# G32R430xx register map
Vendor: Geehy Semiconductor Co., Ltd.; Series: G32R4; File version: 1.0
CPU: CM52 r0p1, little endian, MPU, no FPU, DSP, VTOR, 4 interrupt priority bits
Registers are 32-bit, read-write, reset 0x0 unless marked. A register's access mark holds for its fields unless they carry their own. Offsets are from the block's base; [hi:lo] are bit positions; {n}, {i} and the like mark numbered series.

## COMP — Comparator
Base 0x40003400
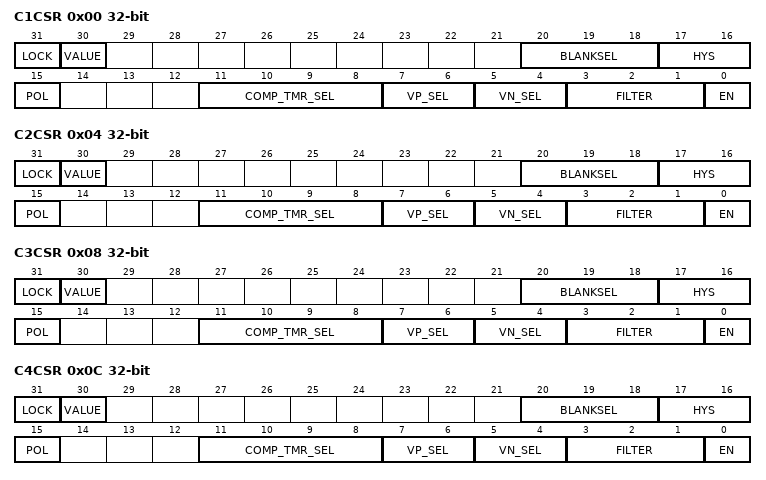
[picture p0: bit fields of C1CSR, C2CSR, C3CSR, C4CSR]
0x00 C1CSR access per field — Comparator 1 control register.
  [31] LOCK rw
  [30] VALUE ro — Comparator outputs the level value before polarity selector and shielding.
  [20:18] BLANKSEL rw — Shielded signal for comparator channel selection.
  [17:16] HYS rw — Delay function enabled
  [15] POL rw — The output polarity of comparator .
  [11:8] COMP_TMR_SEL rw
  [7:6] VP_SEL rw — Comparator 1 positive input voltage select
  [5:4] VN_SEL rw — Comparator 1 negative terminal input voltage select
  [3:1] FILTER rw — Comparator Digital Filter Timing Selection
  [0] EN rw — Module enablement
0x04 C2CSR access per field — Comparator 2 control register.
  [31] LOCK rw
  [30] VALUE ro — Comparator outputs the level value before polarity selector and shielding.
  [20:18] BLANKSEL rw — Shielded signal for comparator channel selection.
  [17:16] HYS rw — Delay function enabled
  [15] POL rw — The output polarity of comparator .
  [11:8] COMP_TMR_SEL rw
  [7:6] VP_SEL rw — Comparator 2 positive input voltage select
  [5:4] VN_SEL rw — Comparator 2 negative terminal input voltage select
  [3:1] FILTER rw — Comparator Digital Filter Timing Selection
  [0] EN rw — Module enablement
0x08 C3CSR access per field — Comparator 3 control register.
  [31] LOCK rw
  [30] VALUE ro — Comparator outputs the level value before polarity selector and shielding.
  [20:18] BLANKSEL rw — Shielded signal for comparator channel selection.
  [17:16] HYS rw — Delay function enabled
  [15] POL rw — The output polarity of comparator .
  [11:8] COMP_TMR_SEL rw
  [7:6] VP_SEL rw — Comparator 3 positive input voltage select
  [5:4] VN_SEL rw — Comparator 3 negative terminal input voltage select
  [3:1] FILTER rw — Comparator Digital Filter Timing Selection
  [0] EN rw — Module enablement
0x0C C4CSR access per field — Comparator 4 control register.
  [31] LOCK rw
  [30] VALUE ro — Comparator outputs the level value before polarity selector and shielding.
  [20:18] BLANKSEL rw — Shielded signal for comparator channel selection.
  [17:16] HYS rw — Delay function enabled
  [15] POL rw — The output polarity of comparator .
  [11:8] COMP_TMR_SEL rw
  [7:6] VP_SEL rw — Comparator 4 positive input voltage select
  [5:4] VN_SEL rw — Comparator 4 negative terminal input voltage select
  [3:1] FILTER rw — Comparator Digital Filter Timing Selection
  [0] EN rw — Module enablement

## PMU — Power manage unit
Base 0x40003800
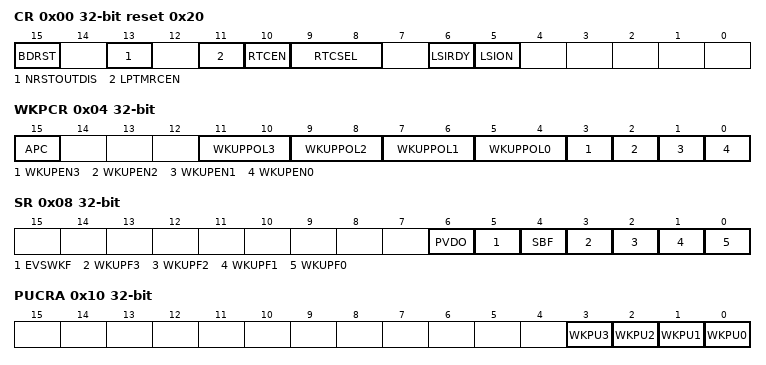
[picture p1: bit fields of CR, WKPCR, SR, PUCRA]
0x00 CR reset 0x20 — Control Register
  [15] BDRST — Reset the bkup area
  [13] NRSTOUTDIS — NRST output pulse to NRST pin enable
  [11] LPTMRCEN — LPTMR clock enable
  [10] RTCEN — RTC clock enable
  [9:8] RTCSEL — RTC Clock Selection
  [6] LSIRDY — LSI Ready Flag Bit
  [5] LSION — LSI Enable
0x04 WKPCR access per field — Low Power Consumption Wake-Up Control Register
  [15] APC rw — Select the status of GPIO when entering standby mode.
  [11:10] WKUPPOL3 rw — The Wake-up Polarity of PD9-WUIO
  [9:8] WKUPPOL2 ro — The Wake-up Polarity of PD0-WUIO
  [7:6] WKUPPOL1 rw — The Wake-up Polarity of PC2-WUIO
  [5:4] WKUPPOL0 rw — The Wake-up Polarity of PC1-WUIO
  [3] WKUPEN3 rw — Activate PD9-WUIO Enable
  [2] WKUPEN2 rw — Activate PD0-WUIO Enable
  [1] WKUPEN1 rw — Activate PC2-WUIO Enable
  [0] WKUPEN0 rw — Activate PC1-WUIO Enable
0x08 SR access per field — Status Register
  [6] PVDO ro — PVD Output 1: VDD voltage is higher than the set value of pvdthsel 0: VDD voltage is lower than the set value of pvdthsel
  [5] EVSWKF rw — EVS wake-up flag, the EVS function can only be used in standby mode.
  [4] SBF rw — 1: The device has entered standby mode. 0: The device has not entered standby mode.
  [3] WKUPF3 rw — The Wake-Up Flag of PD9-WUIO
  [2] WKUPF2 rw — The Wake-Up Flag of PD0-WUIO
  [1] WKUPF1 rw — The Wake-Up Flag of PC2-WUIO
  [0] WKUPF0 rw — The Wake-Up Flag of PC1-WUIO
0x10 PUCRA — Wake up IO pull-up control register
  [n] WKPU{n} (n=0..3) — In standby mode, when APC is enabled, this position is 1, corresponding to the IO being in a pull-up state.
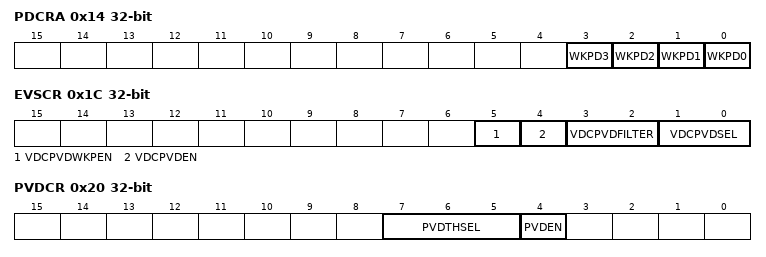
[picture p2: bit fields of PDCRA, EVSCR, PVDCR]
0x14 PDCRA — Wake-up IO Pull-down Control Register
  [n] WKPD{n} (n=0..3) — In standby mode, when APC is enabled, this position is 1, corresponding to the IO being in a pull-down state.
0x1C EVSCR — Power-off Wake-up Control Register
  [5] VDCPVDWKPEN — EVS Pin STANDBY Mode Wake-Up Enable
  [4] VDCPVDEN — EVS Pin Wake-up Enable
  [3:2] VDCPVDFILTER — EVS Pin Filter Configuration
  [1:0] VDCPVDSEL — VDC-VPD Threshold Selection
0x20 PVDCR — PVD Control Register
  [7:5] PVDTHSEL — The detection threshold switch of the programmable voltage detector ranges from a minimum of 2.15V to a maximum of 2.98V, with a default of 000.
  [4] PVDEN — PVD Enable Control Bit
